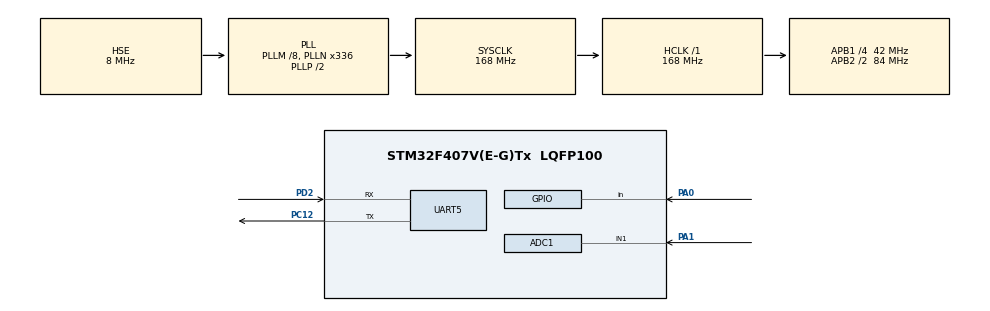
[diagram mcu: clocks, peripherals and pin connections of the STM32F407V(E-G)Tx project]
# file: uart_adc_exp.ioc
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ADC1.Channel-0\#ChannelRegularConversion=ADC_CHANNEL_1
ADC1.NbrOfConversionFlag=1
ADC1.Rank-0\#ChannelRegularConversion=1
ADC1.SamplingTime-0\#ChannelRegularConversion=ADC_SAMPLETIME_3CYCLES
ADC1.master=1
Mcu.Family=STM32F4
Mcu.Name=STM32F407V(E-G)Tx
Mcu.Package=LQFP100
NVIC.PriorityGroup=NVIC_PRIORITYGROUP_0
PA0-WKUP.Signal=GPIO_Input
PA1.Signal=ADCx_IN1
PC12.Mode=Asynchronous
PC12.Signal=UART5_TX
PD2.Mode=Asynchronous
PD2.Signal=UART5_RX
PH0-OSC_IN.Mode=HSE-External-Oscillator
PH0-OSC_IN.Signal=RCC_OSC_IN
PH1-OSC_OUT.Mode=HSE-External-Oscillator
PH1-OSC_OUT.Signal=RCC_OSC_OUT
ProjectManager.HeapSize=0x200
ProjectManager.StackSize=0x400
ProjectManager.TargetToolchain=MDK-ARM V5
RCC.48MHZClocksFreq_Value=48000000
RCC.AHBFreq_Value=168000000
RCC.APB1CLKDivider=RCC_HCLK_DIV4
RCC.APB1Freq_Value=42000000
RCC.APB1TimFreq_Value=84000000
RCC.APB2CLKDivider=RCC_HCLK_DIV2
RCC.APB2Freq_Value=84000000
RCC.APB2TimFreq_Value=168000000
RCC.CortexFreq_Value=168000000
RCC.HCLKFreq_Value=168000000
RCC.HSE_VALUE=8000000
RCC.HSI_VALUE=16000000
RCC.PLLM=8
RCC.PLLN=336
RCC.PLLQ=7
RCC.PLLSourceVirtual=RCC_PLLSOURCE_HSE
RCC.SYSCLKFreq_VALUE=168000000
RCC.SYSCLKSource=RCC_SYSCLKSOURCE_PLLCLK
RCC.VCOOutputFreq_Value=336000000
SH.ADCx_IN1.0=ADC1_IN1,IN1
UART5.VirtualMode=Asynchronous
board=STM32F407G-DISC1

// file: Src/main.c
/* USER CODE BEGIN Header */
/**
  ******************************************************************************
  * @file           : main.c
  * @brief          : Main program body
  ******************************************************************************
  * @attention
  *
  * <h2><center>&copy; Copyright (c) 2019 STMicroelectronics.
  * All rights reserved.</center></h2>
  *
  * This software component is licensed by ST under BSD 3-Clause license,
  * the "License"; You may not use this file except in compliance with the
  * License. You may obtain a copy of the License at:
  *                        opensource.org/licenses/BSD-3-Clause
  *
  ******************************************************************************
  */
/* USER CODE END Header */

#include "main.h"

ADC_HandleTypeDef hadc1;

UART_HandleTypeDef huart5;

void SystemClock_Config(void);
static void MX_GPIO_Init(void);
static void MX_ADC1_Init(void);
static void MX_UART5_Init(void);

int main(void)
{

  /* MCU Configuration--------------------------------------------------------*/

  /* Reset of all peripherals, Initializes the Flash interface and the Systick. */
  HAL_Init();

  /* Configure the system clock */
  SystemClock_Config();

  /* Initialize all configured peripherals */
  MX_GPIO_Init();
  MX_ADC1_Init();
  MX_UART5_Init();

  /* Infinite loop */
  /* USER CODE BEGIN WHILE */
	uint8_t *adc_deg;
  while (1)
  {
    /* USER CODE END WHILE */
HAL_ADC_Start(&hadc1); // ADC OKUMA PORTUNU BASLATTI
	adc_deg[0] =	HAL_ADC_GetValue(&hadc1);
		HAL_ADC_Stop(&hadc1);
		GPIO_PinState read_pin ;

		read_pin = HAL_GPIO_ReadPin(GPIOD, GPIO_PIN_0);
		if(read_pin == GPIO_PIN_SET)//tusa basilmissa uarttan veriyi gönder
			{
		HAL_UART_Transmit(&huart5,adc_deg,1,100);//UART HABERLESME PARAMETRELERI (115200 PARITY=YOK STOPBIT=1 UZUNLUK = 8 BIT)

			while(1)//tustan elini çekene kadar bekle tusa basili iken ard arda veri gönderme
				{
			read_pin = HAL_GPIO_ReadPin(GPIOD, GPIO_PIN_0);
				if(read_pin==GPIO_PIN_RESET)
					break;
			}
		}

  }
}

void SystemClock_Config(void)
{
  RCC_OscInitTypeDef RCC_OscInitStruct = {0};
  RCC_ClkInitTypeDef RCC_ClkInitStruct = {0};

  /** Configure the main internal regulator output voltage
  */
  __HAL_RCC_PWR_CLK_ENABLE();
  __HAL_PWR_VOLTAGESCALING_CONFIG(PWR_REGULATOR_VOLTAGE_SCALE1);
  /** Initializes the CPU, AHB and APB busses clocks
  */
  RCC_OscInitStruct.OscillatorType = RCC_OSCILLATORTYPE_HSE;
  RCC_OscInitStruct.HSEState = RCC_HSE_ON;
  RCC_OscInitStruct.PLL.PLLState = RCC_PLL_ON;
  RCC_OscInitStruct.PLL.PLLSource = RCC_PLLSOURCE_HSE;
  RCC_OscInitStruct.PLL.PLLM = 8;
  RCC_OscInitStruct.PLL.PLLN = 336;
  RCC_OscInitStruct.PLL.PLLP = RCC_PLLP_DIV2;
  RCC_OscInitStruct.PLL.PLLQ = 7;
  if (HAL_RCC_OscConfig(&RCC_OscInitStruct) != HAL_OK)
  {
    Error_Handler();
  }
  /** Initializes the CPU, AHB and APB busses clocks
  */
  RCC_ClkInitStruct.ClockType = RCC_CLOCKTYPE_HCLK|RCC_CLOCKTYPE_SYSCLK
                              |RCC_CLOCKTYPE_PCLK1|RCC_CLOCKTYPE_PCLK2;
  RCC_ClkInitStruct.SYSCLKSource = RCC_SYSCLKSOURCE_PLLCLK;
  RCC_ClkInitStruct.AHBCLKDivider = RCC_SYSCLK_DIV1;
  RCC_ClkInitStruct.APB1CLKDivider = RCC_HCLK_DIV4;
  RCC_ClkInitStruct.APB2CLKDivider = RCC_HCLK_DIV2;

  if (HAL_RCC_ClockConfig(&RCC_ClkInitStruct, FLASH_LATENCY_5) != HAL_OK)
  {
    Error_Handler();
  }
}

static void MX_ADC1_Init(void)
{

  ADC_ChannelConfTypeDef sConfig = {0};

  /** Configure the global features of the ADC (Clock, Resolution, Data Alignment and number of conversion)
  */
  hadc1.Instance = ADC1;
  hadc1.Init.ClockPrescaler = ADC_CLOCK_SYNC_PCLK_DIV4;
  hadc1.Init.Resolution = ADC_RESOLUTION_12B;
  hadc1.Init.ScanConvMode = DISABLE;
  hadc1.Init.ContinuousConvMode = DISABLE;
  hadc1.Init.DiscontinuousConvMode = DISABLE;
  hadc1.Init.ExternalTrigConvEdge = ADC_EXTERNALTRIGCONVEDGE_NONE;
  hadc1.Init.ExternalTrigConv = ADC_SOFTWARE_START;
  hadc1.Init.DataAlign = ADC_DATAALIGN_RIGHT;
  hadc1.Init.NbrOfConversion = 1;
  hadc1.Init.DMAContinuousRequests = DISABLE;
  hadc1.Init.EOCSelection = ADC_EOC_SINGLE_CONV;
  if (HAL_ADC_Init(&hadc1) != HAL_OK)
  {
    Error_Handler();
  }
  /** Configure for the selected ADC regular channel its corresponding rank in the sequencer and its sample time.
  */
  sConfig.Channel = ADC_CHANNEL_1;
  sConfig.Rank = 1;
  sConfig.SamplingTime = ADC_SAMPLETIME_3CYCLES;
  if (HAL_ADC_ConfigChannel(&hadc1, &sConfig) != HAL_OK)
  {
    Error_Handler();
  }

}

static void MX_UART5_Init(void)
{

  huart5.Instance = UART5;
  huart5.Init.BaudRate = 115200;
  huart5.Init.WordLength = UART_WORDLENGTH_8B;
  huart5.Init.StopBits = UART_STOPBITS_1;
  huart5.Init.Parity = UART_PARITY_NONE;
  huart5.Init.Mode = UART_MODE_TX_RX;
  huart5.Init.HwFlowCtl = UART_HWCONTROL_NONE;
  huart5.Init.OverSampling = UART_OVERSAMPLING_16;
  if (HAL_UART_Init(&huart5) != HAL_OK)
  {
    Error_Handler();
  }

}

static void MX_GPIO_Init(void)
{
  GPIO_InitTypeDef GPIO_InitStruct = {0};

  /* GPIO Ports Clock Enable */
  __HAL_RCC_GPIOH_CLK_ENABLE();
  __HAL_RCC_GPIOA_CLK_ENABLE();
  __HAL_RCC_GPIOC_CLK_ENABLE();
  __HAL_RCC_GPIOD_CLK_ENABLE();

  /*Configure GPIO pin : PA0 */
  GPIO_InitStruct.Pin = GPIO_PIN_0;
  GPIO_InitStruct.Mode = GPIO_MODE_INPUT;
  GPIO_InitStruct.Pull = GPIO_NOPULL;
  HAL_GPIO_Init(GPIOA, &GPIO_InitStruct);

}

void Error_Handler(void)
{
}

/************************ (C) COPYRIGHT STMicroelectronics *****END OF FILE****/
